# MKL14Z4 register map
Vendor: Freescale Semiconductor, Inc.; File version: 1.6
CPU: CM0PLUS r0p0, little endian, no MPU, no FPU, 0x2 interrupt priority bits, 0x0 interrupts
Registers are 32-bit, read-write, reset 0x0 unless marked. A register's access mark holds for its fields unless they carry their own. Offsets are from the block's base; [hi:lo] are bit positions; {n}, {i} and the like mark numbered series.

## UART0 — Universal Asynchronous Receiver/Transmitter
Base 0x4006A000; register names take the prefix UART0_
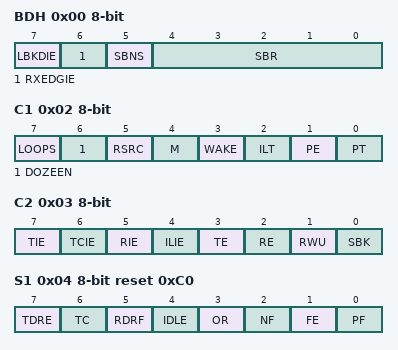
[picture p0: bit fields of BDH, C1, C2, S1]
0x00 BDH 8-bit — UART Baud Rate Register High
  [7] LBKDIE — LIN Break Detect Interrupt Enable (for LBKDIF)
    0=Hardware interrupts from UART _S2[LBKDIF] disabled (use polling); 1=Hardware interrupt requested when UART _S2[LBKDIF] flag is 1
  [6] RXEDGIE — RX Input Active Edge Interrupt Enable (for RXEDGIF)
    0=Hardware interrupts from UART _S2[RXEDGIF] disabled (use polling); 1=Hardware interrupt requested when UART _S2[RXEDGIF] flag is 1
  [5] SBNS — Stop Bit Number Select
    0=One stop bit; 1=Two stop bit
  [4:0] SBR — Baud Rate Modulo Divisor.
0x01 BDL 8-bit reset 0x4 — UART Baud Rate Register Low
  [7:0] SBR — Baud Rate Modulo Divisor
0x02 C1 8-bit — UART Control Register 1
  [7] LOOPS — Loop Mode Select
    0=Normal operation - UART _RX and UART _TX use separate pins; 1=Loop mode or single-wire mode where transmitter outputs are internally connected to receiver input. (See RSRC bit.) UART _RX pin is not used by UART .
  [6] DOZEEN — Doze Enable
    0=UART is enabled in Wait mode; 1=UART is disabled in Wait mode
  [5] RSRC — Receiver Source Select
    0=Provided LOOPS is set, RSRC is cleared, selects internal loop back mode and the UART does not use the UART _RX pins; 1=Single-wire UART mode where the UART _TX pin is connected to the transmitter output and receiver input
  [4] M — 9-Bit or 8-Bit Mode Select
    0=Receiver and transmitter use 8-bit data characters; 1=Receiver and transmitter use 9-bit data characters
  [3] WAKE — Receiver Wakeup Method Select
    0=Idle-line wakeup; 1=Address-mark wakeup
  [2] ILT — Idle Line Type Select
    0=Idle character bit count starts after start bit; 1=Idle character bit count starts after stop bit
  [1] PE — Parity Enable
    0=No hardware parity generation or checking; 1=Parity enabled
  [0] PT — Parity Type
    0=Even parity; 1=Odd parity
0x03 C2 8-bit — UART Control Register 2
  [7] TIE — Transmit Interrupt Enable for TDRE
    0=Hardware interrupts from TDRE disabled; use polling; 1=Hardware interrupt requested when TDRE flag is 1
  [6] TCIE — Transmission Complete Interrupt Enable for TC
    0=Hardware interrupts from TC disabled; use polling; 1=Hardware interrupt requested when TC flag is 1
  [5] RIE — Receiver Interrupt Enable for RDRF
    0=Hardware interrupts from RDRF disabled; use polling; 1=Hardware interrupt requested when RDRF flag is 1
  [4] ILIE — Idle Line Interrupt Enable for IDLE
    0=Hardware interrupts from IDLE disabled; use polling; 1=Hardware interrupt requested when IDLE flag is 1
  [3] TE — Transmitter Enable
    0=Transmitter disabled; 1=Transmitter enabled
  [2] RE — Receiver Enable
    0=Receiver disabled; 1=Receiver enabled
  [1] RWU — Receiver Wakeup Control
    0=Normal UART receiver operation; 1=UART receiver in standby waiting for wakeup condition
  [0] SBK — Send Break
    0=Normal transmitter operation; 1=Queue break character(s) to be sent
0x04 S1 8-bit reset 0xC0 — UART Status Register 1
  [7] TDRE ro — Transmit Data Register Empty Flag
    0=Transmit data buffer full; 1=Transmit data buffer empty
  [6] TC ro — Transmission Complete Flag
    0=Transmitter active (sending data, a preamble, or a break); 1=Transmitter idle (transmission activity complete)
  [5] RDRF ro — Receive Data Register Full Flag
    0=Receive data buffer empty; 1=Receive data buffer full
  [4] IDLE — Idle Line Flag
    0=No idle line detected; 1=Idle line was detected
  [3] OR — Receiver Overrun Flag
    0=No overrun; 1=Receive overrun (new UART data lost)
  [2] NF — Noise Flag
    0=No noise detected; 1=Noise detected in the received character in UART _D
  [1] FE — Framing Error Flag
    0=No framing error detected. This does not guarantee the framing is correct.; 1=Framing error
  [0] PF — Parity Error Flag
    0=No parity error; 1=Parity error
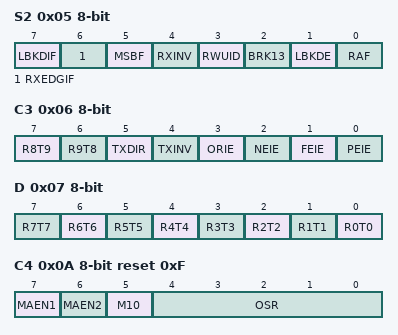
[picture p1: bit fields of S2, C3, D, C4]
0x05 S2 8-bit — UART Status Register 2
  [7] LBKDIF — LIN Break Detect Interrupt Flag
    0=No LIN break character has been detected; 1=LIN break character has been detected
  [6] RXEDGIF — UART _RX Pin Active Edge Interrupt Flag
    0=No active edge on the receive pin has occurred; 1=An active edge on the receive pin has occurred
  [5] MSBF — MSB First
    0=LSB (bit0) is the first bit that is transmitted following the start bit. Further, the first bit received after the start bit is identified as bit0.; 1=MSB (bit9, bit8, bit7 or bit6) is the first bit that is transmitted following the start bit depending on the setting of C1[M], C1[PE] and C4[M10]. Further, the first bit received after the start bit is identified as bit9, bit8, bit7 or bit6 depending on the setting of C1[M] and C1[PE].
  [4] RXINV — Receive Data Inversion
    0=Receive data not inverted; 1=Receive data inverted
  [3] RWUID — Receive Wake Up Idle Detect
    0=During receive standby state (RWU = 1), the IDLE bit does not get set upon detection of an idle character; 1=During receive standby state (RWU = 1), the IDLE bit gets set upon detection of an idle character
  [2] BRK13 — Break Character Generation Length
    0=Break character is transmitted with length of 10 bit times (if M = 0, SBNS = 0) or 11 (if M = 1, SBNS = 0 or M = 0, SBNS = 1) or 12 (if M = 1, SBNS = 1 or M10 = 1, SNBS = 0) or 13 (if M10 = 1, SNBS = 1); 1=Break character is transmitted with length of 13 bit times (if M = 0, SBNS = 0) or 14 (if M = 1, SBNS = 0 or M = 0, SBNS = 1) or 15 (if M = 1, SBNS = 1 or M10 = 1, SNBS = 0) or 16 (if M10 = 1, SNBS = 1)
  [1] LBKDE — LIN Break Detection Enable
    0=Break character is detected at length 10 bit times (if M = 0, SBNS = 0) or 11 (if M = 1, SBNS = 0 or M = 0, SBNS = 1) or 12 (if M = 1, SBNS = 1 or M10 = 1, SNBS = 0) or 13 (if M10 = 1, SNBS = 1); 1=Break character is detected at length of 11 bit times (if M = 0, SBNS = 0) or 12 (if M = 1, SBNS = 0 or M = 0, SBNS = 1) or 14 (if M = 1, SBNS = 1 or M10 = 1, SNBS = 0) or 15 (if M10 = 1, SNBS = 1)
  [0] RAF ro — Receiver Active Flag
    0=UART receiver idle waiting for a start bit; 1=UART receiver active ( UART _RXD input not idle)
0x06 C3 8-bit — UART Control Register 3
  [7] R8T9 — Receive Bit 8 / Transmit Bit 9
  [6] R9T8 — Receive Bit 9 / Transmit Bit 8
  [5] TXDIR — UART _TX Pin Direction in Single-Wire Mode
    0=UART _TXD pin is an input in single-wire mode; 1=UART _TXD pin is an output in single-wire mode
  [4] TXINV — Transmit Data Inversion
    0=Transmit data not inverted; 1=Transmit data inverted
  [3] ORIE — Overrun Interrupt Enable
    0=OR interrupts disabled; use polling; 1=Hardware interrupt requested when OR is set
  [2] NEIE — Noise Error Interrupt Enable
    0=NF interrupts disabled; use polling; 1=Hardware interrupt requested when NF is set
  [1] FEIE — Framing Error Interrupt Enable
    0=FE interrupts disabled; use polling; 1=Hardware interrupt requested when FE is set
  [0] PEIE — Parity Error Interrupt Enable
    0=PF interrupts disabled; use polling); 1=Hardware interrupt requested when PF is set
0x07 D 8-bit — UART Data Register
  [n] R{n}T{n} (n=0..7) — Read receive data buffer {n} or write transmit data buffer {n}.
0x08 MA1 8-bit — UART Match Address Registers 1
  [7:0] MA — Match Address
0x09 MA2 8-bit — UART Match Address Registers 2
  [7:0] MA — Match Address
0x0A C4 8-bit reset 0xF — UART Control Register 4
  [7] MAEN1 — Match Address Mode Enable 1
    0=All data received is transferred to the data buffer if MAEN2 is cleared; 1=All data received with the most significant bit cleared, is discarded. All data received with the most significant bit set, is compared with contents of MA1 register. If no match occurs, the data is discarded. If match occurs, data is transferred to the data buffer.
  [6] MAEN2 — Match Address Mode Enable 2
    0=All data received is transferred to the data buffer if MAEN1 is cleared; 1=All data received with the most significant bit cleared, is discarded. All data received with the most significant bit set, is compared with contents of MA2 register. If no match occurs, the data is discarded. If match occurs, data is transferred to the data buffer.
  [5] M10 — 10-bit Mode select
    0=Receiver and transmitter use 8-bit or 9-bit data characters; 1=Receiver and transmitter use 10-bit data characters
  [4:0] OSR — Over Sampling Ratio
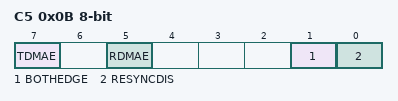
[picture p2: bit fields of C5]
0x0B C5 8-bit — UART Control Register 5
  [7] TDMAE — Transmitter DMA Enable
    0=DMA request disabled; 1=DMA request enabled
  [5] RDMAE — Receiver Full DMA Enable
    0=DMA request disabled; 1=DMA request enabled
  [1] BOTHEDGE — Both Edge Sampling
    0=Receiver samples input data using the rising edge of the baud rate clock; 1=Receiver samples input data using the rising and falling edge of the baud rate clock
  [0] RESYNCDIS — Resynchronization Disable
    0=Resynchronization during received data word is supported; 1=Resynchronization during received data word is disabled
